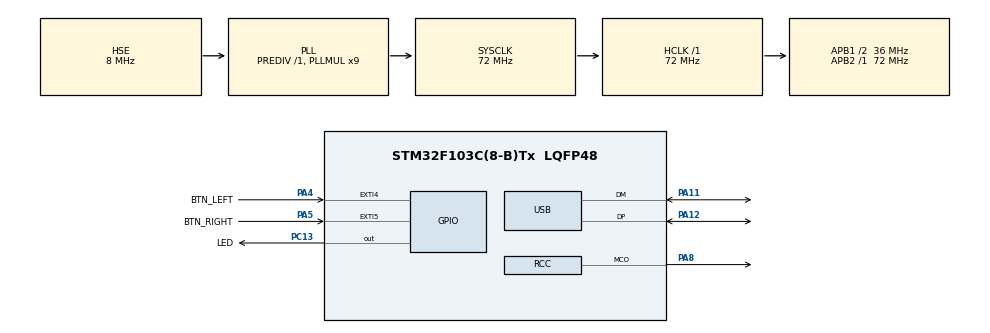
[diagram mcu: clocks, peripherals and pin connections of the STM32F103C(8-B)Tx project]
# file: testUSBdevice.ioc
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Mcu.Family=STM32F1
Mcu.Name=STM32F103C(8-B)Tx
Mcu.Package=LQFP48
NVIC.EXTI4_IRQn=true\:0\:0\:false\:false\:true\:true\:true\:true
NVIC.EXTI9_5_IRQn=true\:0\:0\:false\:false\:true\:true\:true\:true
NVIC.PriorityGroup=NVIC_PRIORITYGROUP_4
NVIC.USB_LP_CAN1_RX0_IRQn=true\:0\:0\:false\:false\:true\:false\:true\:true
PA11.Mode=Device
PA11.Signal=USB_DM
PA12.Mode=Device
PA12.Signal=USB_DP
PA13.Mode=Trace_Asynchronous_SW
PA13.Signal=SYS_JTMS-SWDIO
PA14.Mode=Trace_Asynchronous_SW
PA14.Signal=SYS_JTCK-SWCLK
PA4.GPIO_Label=BTN_LEFT
PA4.GPIO_ModeDefaultEXTI=GPIO_MODE_IT_RISING_FALLING
PA4.GPIO_PuPd=GPIO_PULLUP
PA4.Signal=GPXTI4
PA5.GPIO_Label=BTN_RIGHT
PA5.GPIO_ModeDefaultEXTI=GPIO_MODE_IT_RISING_FALLING
PA5.GPIO_PuPd=GPIO_PULLUP
PA5.Signal=GPXTI5
PA8.Mode=Clock-out
PA8.Signal=RCC_MCO
PB3.Mode=Trace_Asynchronous_SW
PB3.Signal=SYS_JTDO-TRACESWO
PC13-TAMPER-RTC.GPIO_Label=LED
PC13-TAMPER-RTC.PinState=GPIO_PIN_SET
PC13-TAMPER-RTC.Signal=GPIO_Output
PD0-OSC_IN.Mode=HSE-External-Oscillator
PD0-OSC_IN.Signal=RCC_OSC_IN
PD1-OSC_OUT.Mode=HSE-External-Oscillator
PD1-OSC_OUT.Signal=RCC_OSC_OUT
ProjectManager.HeapSize=0x1000
ProjectManager.StackSize=0x400
ProjectManager.TargetToolchain=STM32CubeIDE
RCC.AHBFreq_Value=72000000
RCC.APB1CLKDivider=RCC_HCLK_DIV2
RCC.APB1Freq_Value=36000000
RCC.APB1TimFreq_Value=72000000
RCC.APB2Freq_Value=72000000
RCC.APB2TimFreq_Value=72000000
RCC.HCLKFreq_Value=72000000
RCC.PLLMUL=RCC_PLL_MUL9
RCC.RCC_MCOSource=RCC_MCO1SOURCE_PLLCLK
RCC.SYSCLKFreq_VALUE=72000000
RCC.SYSCLKSource=RCC_SYSCLKSOURCE_PLLCLK
RCC.USBFreq_Value=48000000
RCC.USBPrescaler=RCC_USBCLKSOURCE_PLL_DIV1_5
USB_DEVICE.CLASS_NAME_FS=CUSTOM_HID
USB_DEVICE.LANGID_STRING=1033
USB_DEVICE.MANUFACTURER_STRING=Immersys
USB_DEVICE.PID_CUSTOMHID_FS=65535
USB_DEVICE.PRODUCT_STRING_CUSTOMHID_FS=Forklift Controls
USB_DEVICE.USBD_CUSTOMHID_OUTREPORT_BUF_SIZE=8
USB_DEVICE.USBD_CUSTOM_HID_REPORT_DESC_SIZE=29
USB_DEVICE.VID=1155
USB_DEVICE.VirtualMode=CustomHid
USB_DEVICE.VirtualModeFS=Custom_Hid_FS
VP_USB_DEVICE_VS_USB_DEVICE_CUSTOM_HID_FS.Mode=CUSTOM_HID_FS
board=custom

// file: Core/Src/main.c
/* USER CODE BEGIN Header */
/**
  ******************************************************************************
  * @file           : main.c
  * @brief          : Main program body
  ******************************************************************************
  * @attention
  *
  * Copyright (c) 2024 STMicroelectronics.
  * All rights reserved.
  *
  * This software is licensed under terms that can be found in the LICENSE file
  * in the root directory of this software component.
  * If no LICENSE file comes with this software, it is provided AS-IS.
  *
  ******************************************************************************
  */
/* USER CODE END Header */
#include "main.h"
#include "usb_device.h"
#include "gpio.h"

/* USER CODE BEGIN Includes */
#include "usbd_customhid.h"
#include "joystick.h"
/* USER CODE END Includes */

/* USER CODE BEGIN PD */
HAL_GPIO_MODULE_ENABLED
/* USER CODE END PD */

/* USER CODE BEGIN PV */
extern USBD_HandleTypeDef hUsbDeviceFS;
joystick_t joystick = {
		.report_id = 1,
	.switches = {
		.btn_right = 1, .btn_left = 1, .padding = 0
	}
};

bool button_changed;

/* USER CODE END PV */

void SystemClock_Config(void);

int main(void)
{

  /* USER CODE BEGIN 1 */
	button_changed = false;
  /* USER CODE END 1 */

  /* MCU Configuration--------------------------------------------------------*/

  /* Reset of all peripherals, Initializes the Flash interface and the Systick. */
  HAL_Init();

  /* Configure the system clock */
  SystemClock_Config();

  /* Initialize all configured peripherals */
  MX_GPIO_Init();
  MX_USB_DEVICE_Init();

  /* Infinite loop */
  while (1)
  {

    /* USER CODE BEGIN 3 */
	  if(button_changed){
		  button_changed = false;
		  USBD_CUSTOM_HID_SendReport(&hUsbDeviceFS, (uint8_t *)&joystick, sizeof(joystick));
	  }
  }
  /* USER CODE END 3 */
}

void SystemClock_Config(void)
{
  RCC_OscInitTypeDef RCC_OscInitStruct = {0};
  RCC_ClkInitTypeDef RCC_ClkInitStruct = {0};
  RCC_PeriphCLKInitTypeDef PeriphClkInit = {0};

  /** Initializes the RCC Oscillators according to the specified parameters
  * in the RCC_OscInitTypeDef structure.
  */
  RCC_OscInitStruct.OscillatorType = RCC_OSCILLATORTYPE_HSE;
  RCC_OscInitStruct.HSEState = RCC_HSE_ON;
  RCC_OscInitStruct.HSEPredivValue = RCC_HSE_PREDIV_DIV1;
  RCC_OscInitStruct.HSIState = RCC_HSI_ON;
  RCC_OscInitStruct.PLL.PLLState = RCC_PLL_ON;
  RCC_OscInitStruct.PLL.PLLSource = RCC_PLLSOURCE_HSE;
  RCC_OscInitStruct.PLL.PLLMUL = RCC_PLL_MUL9;
  if (HAL_RCC_OscConfig(&RCC_OscInitStruct) != HAL_OK)
  {
    Error_Handler();
  }

  /** Initializes the CPU, AHB and APB buses clocks
  */
  RCC_ClkInitStruct.ClockType = RCC_CLOCKTYPE_HCLK|RCC_CLOCKTYPE_SYSCLK
                              |RCC_CLOCKTYPE_PCLK1|RCC_CLOCKTYPE_PCLK2;
  RCC_ClkInitStruct.SYSCLKSource = RCC_SYSCLKSOURCE_PLLCLK;
  RCC_ClkInitStruct.AHBCLKDivider = RCC_SYSCLK_DIV1;
  RCC_ClkInitStruct.APB1CLKDivider = RCC_HCLK_DIV2;
  RCC_ClkInitStruct.APB2CLKDivider = RCC_HCLK_DIV1;

  if (HAL_RCC_ClockConfig(&RCC_ClkInitStruct, FLASH_LATENCY_2) != HAL_OK)
  {
    Error_Handler();
  }
  PeriphClkInit.PeriphClockSelection = RCC_PERIPHCLK_USB;
  PeriphClkInit.UsbClockSelection = RCC_USBCLKSOURCE_PLL_DIV1_5;
  if (HAL_RCCEx_PeriphCLKConfig(&PeriphClkInit) != HAL_OK)
  {
    Error_Handler();
  }
  HAL_RCC_MCOConfig(RCC_MCO, RCC_MCO1SOURCE_PLLCLK, RCC_MCODIV_1);
}

void Error_Handler(void)
{
  __disable_irq();
  while (1)
  {
  }
}
